# platform_designer_hps_system_hps_0_hps register map
Vendor: default_vendor.com; File version: 0.0
Registers are 32-bit, read-write, reset 0x0 unless marked. A register's access mark holds for its fields unless they carry their own. Offsets are from the block's base; [hi:lo] are bit positions; 'fields as' and 'values as' point back to an identical list.

## clkmgr — Registers in the Clock Manager module
Base 0xFFD04000
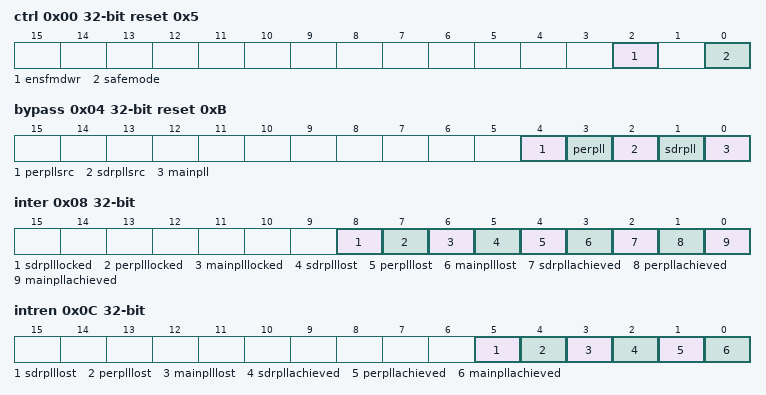
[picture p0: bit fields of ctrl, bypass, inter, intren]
0x00 ctrl reset 0x5 — Contains fields that control the entire Clock Manager.
  [2] ensfmdwr — When set the Clock Manager will respond to a Safe Mode request from the Reset Manager on a warm reset by setting the Safe Mode bit. When clear the clock manager will not set the the Safe Mode bit on a warm reset This bit is cleared on a cold reset. Warm reset has no affect on this bit.
  [0] safemode write-1-clears — When set the Clock Manager is in Safe Mode. In Safe Mode Clock Manager register settings defining clock behavior are ignored and clocks are set to a Safe Mode state.In Safe Mode all clocks with the optional exception of debug clocks, are directly generated from the EOSC1 clock input, all PLLs are bypassed, all programmable dividers are set to 1 and all clocks are enabled. This bit should only be cleared when clocks have been correctly configured This field is set on a cold reset and optionally on a warm reset and may not be set by SW.
0x04 bypass reset 0xB — Contains fields that control bypassing each PLL.
  [4] perpllsrc — This bit defines the bypass source forPeripheral PLL. When changing fields that affect VCO lock the PLL must be bypassed and this bit must be set to OSC1_CLK. The reset value for this bit is applied on a cold reset. Warm reset has no affect on this bit.
    0=SELECT_EOSC1; 1=SELECT_INPUT_MUX
  [3] perpll — When set, causes the Peripheral PLL VCO and counters to be bypassed so that all clocks generated by the Peripheral PLL are directly driven from either eosc1_clk or the Peripheral PLL input clock. The bypass clock source for Peripheral PLL is determined by the Peripheral PLL Bypass Source Register bit. The reset value for this bit is applied on a cold reset. Warm reset has no affect on this bit.
  [2] sdrpllsrc — This bit defines the bypass source forSDRAM PLL. When changing fields that affect VCO lock the PLL must be bypassed and this bit must be set to OSC1_CLK. The reset value for this bit is applied on a cold reset. Warm reset has no affect on this bit.
    0=SELECT_EOSC1; 1=SELECT_INPUT_MUX
  [1] sdrpll — When set, causes the SDRAM PLL VCO and counters to be bypassed so that all clocks generated by the SDRAM PLL are directly driven from either eosc1_clk or the SDRAM PLL input clock. The bypass clock source for SDRAM PLL is determined by the SDRAM PLL Bypass Source Register bit. The reset value for this bit is applied on a cold reset. Warm reset has no affect on this bit.
  [0] mainpll — When set, causes the Main PLL VCO and counters to be bypassed so that all clocks generated by the Main PLL are directly driven from the Main PLL input clock. The bypass source for Main PLL is the external eosc1_clk. The reset value for this bit is applied on a cold reset. Warm reset has no affect on this bit.
0x08 inter (reset mask 0xFFFFFE3F) — Contains fields that indicate the PLL lock status. Fields are only reset by a cold reset.
  [8] sdrplllocked ro — If 1, the SDRAM PLL is currently locked. If 0, the SDRAM PLL is currently not locked.
  [7] perplllocked ro — If 1, the Peripheral PLL is currently locked. If 0, the Peripheral PLL is currently not locked.
  [6] mainplllocked ro — If 1, the Main PLL is currently locked. If 0, the Main PLL is currently not locked.
  [5] sdrplllost write-1-clears — If 1, the SDRAM PLL has lost lock at least once since this bit was cleared. If 0, the SDRAM PLL has not lost lock since this bit was cleared.
  [4] perplllost write-1-clears — If 1, the Peripheral PLL has lost lock at least once since this bit was cleared. If 0, the Peripheral PLL has not lost lock since this bit was cleared.
  [3] mainplllost write-1-clears — If 1, the Main PLL has lost lock at least once since this bit was cleared. If 0, the Main PLL has not lost lock since this bit was cleared.
  [2] sdrpllachieved write-1-clears — If 1, the SDRAM PLL has achieved lock at least once since this bit was cleared. If 0, the SDRAM PLL has not achieved lock since this bit was cleared.
  [1] perpllachieved write-1-clears — If 1, the Peripheral PLL has achieved lock at least once since this bit was cleared. If 0, the Peripheral PLL has not achieved lock since this bit was cleared.
  [0] mainpllachieved write-1-clears — If 1, the Main PLL has achieved lock at least once since this bit was cleared. If 0, the Main PLL has not achieved lock since this bit was cleared.
0x0C intren — Contain fields that enable the interrupt. Fields are only reset by a cold reset.
  [5] sdrplllost — When set to 1, the SDRAM PLL lost lock bit is ORed into the Clock Manager interrupt output. When set to 0 the SDRAM PLL lost lock bit is not ORed into the Clock Manager interrupt output.
  [4] perplllost — When set to 1, the Peripheral PLL lost lock bit is ORed into the Clock Manager interrupt output. When set to 0 the Peripheral PLL lost lock bit is not ORed into the Clock Manager interrupt output.
  [3] mainplllost — When set to 1, the Main PLL lost lock bit is ORed into the Clock Manager interrupt output. When set to 0 the Main PLL lost lock bit is not ORed into the Clock Manager interrupt output.
  [2] sdrpllachieved — When set to 1, the SDRAM PLL achieved lock bit is ORed into the Clock Manager interrupt output. When set to 0 the SDRAM PLL achieved lock bit is not ORed into the Clock Manager interrupt output.
  [1] perpllachieved — When set to 1, the Peripheral PLL achieved lock bit is ORed into the Clock Manager interrupt output. When set to 0 the Peripheral PLL achieved lock bit is not ORed into the Clock Manager interrupt output.
  [0] mainpllachieved — When set to 1, the Main PLL achieved lock bit is ORed into the Clock Manager interrupt output. When set to 0 the Main PLL achieved lock bit is not ORed into the Clock Manager interrupt output.
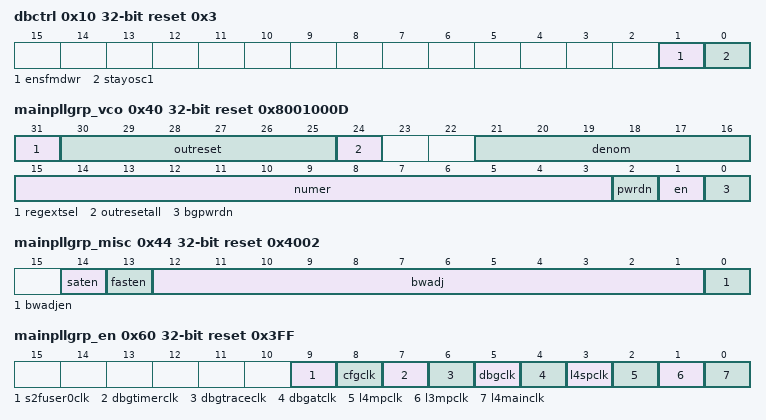
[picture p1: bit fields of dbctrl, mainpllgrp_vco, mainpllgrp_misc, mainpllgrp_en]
0x10 dbctrl reset 0x3 — Contains fields that control the debug clocks.
  [1] ensfmdwr — When this bit is set the debug clocks will be affected by the assertion of Safe Mode on a warm reset if Stay OSC1 is not set. When this bit is clear the debug clocks will not be affected by the assertion of Safe Mode on a warm reset. If Debug Clocks are in Safe Mode they are taken out of Safe Mode when the Safe Mode bit is cleared independent of this bit.The reset value of this bit is applied on a cold reset; warm reset has no affect on this bit.
  [0] stayosc1 — When this bit is set the debug root clock (Main PLL C2 output) will always be bypassed to the EOSC1_clk independent of any other clock manager settings. When clear the debug source will be a function of register settings in the clock manager. Clocks affected by this bit are dbg_at_clk, dbg_clk, dbg_trace_clk, and dbg_timer_clk. The reset value for this bit is applied on a cold reset. Warm reset has no affect on this bit.
0x14 stat ro — Provides status of Hardware Managed Clock transition State Machine.
  [0] busy — This read only bit indicates that the Hardware Managed clock's state machine is active. If the state machine is active, then the clocks are in transition. Software should poll this bit after changing the source of internal clocks when writing to the BYPASS, CTRL or DBCTRL registers. Immediately following writes to any of these registers, SW should wait until this bit is IDLE before proceeding with any other register writes in the Clock Manager. The reset value of this bit is applied on a cold reset; warm reset has no affect on this bit.
    0=IDLE; 1=BUSY
0x40 mainpllgrp_vco reset 0x8001000D — Contains settings that control the Main PLL VCO. The VCO output frequency is the input frequency multiplied by the numerator (M+1) and divided by the denominator (N+1). The VCO input clock source is always eosc1_clk. Fields are only reset by a cold reset.
  [31] regextsel — If set to '1', the external regulator is selected for the PLL. If set to '0', the internal regulator is slected. It is strongly recommended to select the external regulator while the PLL is not enabled (in reset), and then disable the external regulater once the PLL becomes enabled. Software should simulateously update the 'Enable' bit and the 'External Regulator Input Select' in the same write access to the VCO register. When the 'Enable' bit is clear, the 'External Regulator Input Select' should be set, and vice versa. The reset value of this bit is applied on a cold reset; warm reset has no affect on this bit.
  [30:25] outreset — Resets the individual PLL output counter. For software to change the PLL output counter without producing glitches on the respective clock, SW must set the VCO register respective Output Counter Reset bit. Software then polls the respective Output Counter Reset Acknowledge bit in the Output Counter Reset Ack Status Register. Software then writes the appropriate counter register, and then clears the respective VCO register Output Counter Reset bit. LSB 'outreset[0]' corresponds to PLL output clock C0, etc. If set to '1', reset output divider, no clock output from counter. If set to '0', counter is not reset. The reset value of this bit is applied on a cold reset; warm reset has no affect on this bit.
  [24] outresetall — Before releasing Bypass, All Output Counter Reset must be set and cleared by software for correct clock operation. If '1', Reset phase multiplexer and all output counter state. So that after the assertion all the clocks output are start from rising edge align. If '0', phase multiplexer and output counter state not reset and no change to the phase of the clock outputs.
  [21:16] denom — Denominator in VCO output frequency equation. For incremental frequency change, if the new value lead to less than 20% of the frequency change, this value can be changed without resetting the PLL. The Numerator and Denominator can not be changed at the same time for incremental frequency changed.
  [15:3] numer — Numerator in VCO output frequency equation. For incremental frequency change, if the new value lead to less than 20% of the frequency change, this value can be changed without resetting the PLL. The Numerator and Denominator can not be changed at the same time for incremental frequency changed.
  [2] pwrdn — If '1', power down analog circuitry. If '0', analog circuitry not powered down.
  [1] en — If '1', VCO is enabled. If '0', VCO is in reset.
  [0] bgpwrdn — If '1', powers down bandgap. If '0', bandgap is not power down.
0x44 mainpllgrp_misc reset 0x4002 — Contains VCO control signals and other PLL control signals need to be controllable through register. Fields are only reset by a cold reset.
  [14] saten — Enables saturation behavior.
  [13] fasten — Enables fast locking circuit.
  [12:1] bwadj — Provides Loop Bandwidth Adjust value.
  [0] bwadjen — If set to 1, the Loop Bandwidth Adjust value comes from the Loop Bandwidth Adjust field. If set to 0, the Loop Bandwidth Adjust value equals the M field divided by 2 value of the VCO Control Register. The M divided by 2 is the upper 12 bits (12:1) of the M field in the VCO register.
0x48 mainpllgrp_mpuclk — Contains settings that control clock mpu_clk generated from the C0 output of the Main PLL. Only reset by a cold reset.
  [8:0] cnt — Divides the VCO/2 frequency by the value+1 in this field.
0x4C mainpllgrp_mainclk — Contains settings that control clock main_clk generated from the C1 output of the Main PLL. Only reset by a cold reset.
  [8:0] cnt — Divides the VCO/4 frequency by the value+1 in this field.
0x50 mainpllgrp_dbgatclk — Contains settings that control clock dbg_base_clk generated from the C2 output of the Main PLL. Only reset by a cold reset.
  fields as mainpllgrp_mainclk
0x54 mainpllgrp_mainqspiclk reset 0x3 — Contains settings that control clock main_qspi_clk generated from the C3 output of the Main PLL. Only reset by a cold reset.
  [8:0] cnt — Divides the VCO frequency by the value+1 in this field.
0x58 mainpllgrp_mainnandsdmmcclk reset 0x3 — Contains settings that control clock main_nand_sdmmc_clk generated from the C4 output of the Main PLL. Only reset by a cold reset.
  [8:0] cnt — Divides the VCO frequency by the value+1 in this field.
0x5C mainpllgrp_cfgs2fuser0clk reset 0xF — Contains settings that control clock cfg_s2f_user0_clk generated from the C5 output of the Main PLL. Qsys and user documenation refer to cfg_s2f_user0_clk as cfg_h2f_user0_clk. Only reset by a cold reset.
  [8:0] cnt — Divides the VCO frequency by the value+1 in this field.
0x60 mainpllgrp_en reset 0x3FF — Contains fields that control clock enables for clocks derived from the Main PLL. 1: The clock is enabled. 0: The clock is disabled. Fields are only reset by a cold reset.
  [9] s2fuser0clk — Enables clock s2f_user0_clk output. Qsys and user documenation refer to s2f_user0_clk as h2f_user0_clk.
  [8] cfgclk — Enables clock cfg_clk output
  [7] dbgtimerclk — Enables clock dbg_timer_clk output
  [6] dbgtraceclk — Enables clock dbg_trace_clk output
  [5] dbgclk — Enables clock dbg_clk output
  [4] dbgatclk — Enables clock dbg_at_clk output
  [3] l4spclk — Enables clock l4_sp_clk output
  [2] l4mpclk — Enables clock l4_mp_clk output
  [1] l3mpclk — Enables clock l3_mp_clk output
  [0] l4mainclk — Enables clock l4_main_clk output
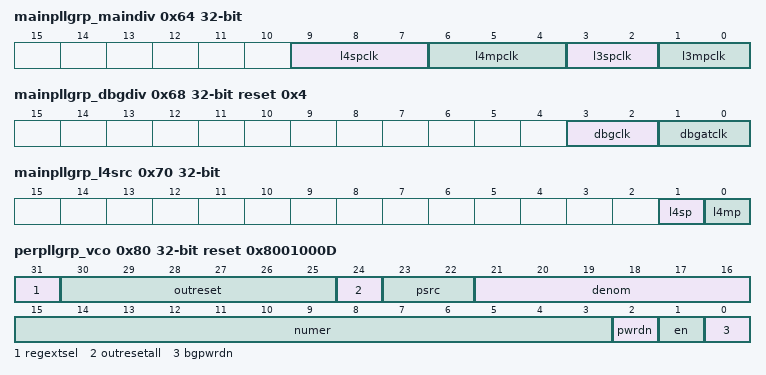
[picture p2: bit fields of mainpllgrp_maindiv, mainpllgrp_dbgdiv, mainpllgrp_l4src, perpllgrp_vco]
0x64 mainpllgrp_maindiv — Contains fields that control clock dividers for main clocks derived from the Main PLL Fields are only reset by a cold reset.
  [9:7] l4spclk — The l4_sp_clk is divided down from the periph_base_clk by the value specified in this field.
    0=Div1; 1=Div2; 2=Div4; 3=Div8; 4=Div16
  [6:4] l4mpclk — The l4_mp_clk is divided down from the periph_base_clk by the value specified in this field.
    0=Div1; 1=Div2; 2=Div4; 3=Div8; 4=Div16
  [3:2] l3spclk — The l3_sp_clk is divided down from the l3_mp_clk by the value specified in this field.
    0=Div1; 1=Div2
  [1:0] l3mpclk — The l3_mp_clk is divided down from the l3_main_clk by the value specified in this field.
    0=Div1; 1=Div2
0x68 mainpllgrp_dbgdiv reset 0x4 — Contains fields that control clock dividers for debug clocks derived from the Main PLL Fields are only reset by a cold reset.
  [3:2] dbgclk — The dbg_clk is divided down from the dbg_at_clk by the value specified in this field.
    1=Div2; 2=Div4
  [1:0] dbgatclk — The dbg_at_clk is divided down from the C2 output of the Main PLL by the value specified in this field.
    0=Div1; 1=Div2; 2=Div4
0x6C mainpllgrp_tracediv — Contains a field that controls the clock divider for the debug trace clock derived from the Main PLL Only reset by a cold reset.
  [2:0] traceclk — The dbg_trace_clk is divided down from the C2 output of the Main PLL by the value specified in this field.
    0=Div1; 1=Div2; 2=Div4; 3=Div8; 4=Div16
0x70 mainpllgrp_l4src — Contains fields that select the clock source for L4 MP and SP APB interconnect Fields are only reset by a cold reset.
  [1] l4sp — Selects the source for l4_sp_clk
    0=MainPLL; 1=PeriphPLL
  [0] l4mp — Selects the source for l4_mp_clk
    0=MainPLL; 1=PeriphPLL
0x74 mainpllgrp_stat ro — Contains Output Clock Counter Reset acknowledge status.
  [5:0] outresetack — These read only bits per PLL output indicate that the PLL has received the Output Reset Counter request and has gracefully stopped the respective PLL output clock. For software to change the PLL output counter without producing glitches on the respective clock, SW must set the VCO register respective Output Counter Reset bit. Software then polls the respective Output Counter Reset Acknowledge bit in the Output Counter Reset Ack Status Register. Software then writes the appropriate counter register, and then clears the respective VCO register Output Counter Reset bit. The reset value of this bit is applied on a cold reset; warm reset has no affect on this bit.
    0=IDLE; 1=ACK_RECEIVED
0x80 perpllgrp_vco reset 0x8001000D — Contains settings that control the Peripheral PLL VCO. The VCO output frequency is the input frequency multiplied by the numerator (M+1) and divided by the denominator (N+1). Fields are only reset by a cold reset.
  [31] regextsel — If set to '1', the external regulator is selected for the PLL. If set to '0', the internal regulator is slected. It is strongly recommended to select the external regulator while the PLL is not enabled (in reset), and then disable the external regulater once the PLL becomes enabled. Software should simulateously update the 'Enable' bit and the 'External Regulator Input Select' in the same write access to the VCO register. When the 'Enable' bit is clear, the 'External Regulator Input Select' should be set, and vice versa. The reset value of this bit is applied on a cold reset; warm reset has no affect on this bit.
  [30:25] outreset — Resets the individual PLL output counter. For software to change the PLL output counter without producing glitches on the respective clock, SW must set the VCO register respective Output Counter Reset bit. Software then polls the respective Output Counter Reset Acknowledge bit in the Output Counter Reset Ack Status Register. Software then writes the appropriate counter register, and then clears the respective VCO register Output Counter Reset bit. LSB 'outreset[0]' corresponds to PLL output clock C0, etc. If set to '1', reset output divider, no clock output from counter. If set to '0', counter is not reset. The reset value of this bit is applied on a cold reset; warm reset has no affect on this bit.
  [24] outresetall — Before releasing Bypass, All Output Counter Reset must be set and cleared by software for correct clock operation. If '1', Reset phase multiplexer and all output counter state. So that after the assertion all the clocks output are start from rising edge align. If '0', phase multiplexer and output counter state not reset and no change to the phase of the clock outputs.
  [23:22] psrc — Controls the VCO input clock source. Qsys and user documenation refer to f2s_periph_ref_clk as f2h_periph_ref_clk.
    0=EOSC1; 1=EOSC2; 2=F2S_Periph_Ref
  [21:16] denom — Denominator in VCO output frequency equation. For incremental frequency change, if the new value lead to less than 20% of the frequency change, this value can be changed without resetting the PLL. The Numerator and Denominator can not be changed at the same time for incremental frequency changed.
  [15:3] numer — Numerator in VCO output frequency equation. For incremental frequency change, if the new value lead to less than 20% of the frequency change, this value can be changed without resetting the PLL. The Numerator and Denominator can not be changed at the same time for incremental frequency changed.
  [2] pwrdn — If '1', power down analog circuitry. If '0', analog circuitry not powered down.
  [1] en — If '1', VCO is enabled. If '0', VCO is in reset.
  [0] bgpwrdn — If '1', powers down bandgap. If '0', bandgap is not power down.
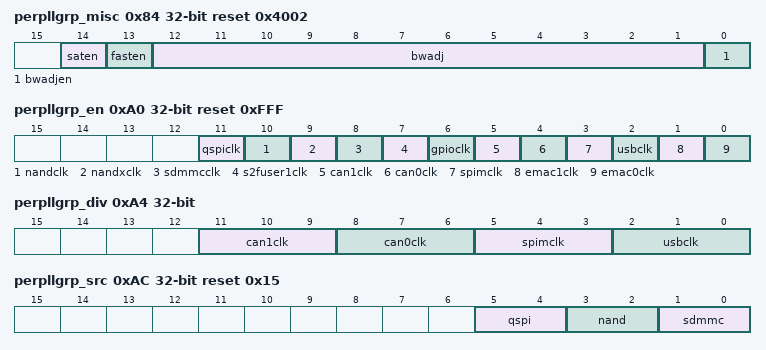
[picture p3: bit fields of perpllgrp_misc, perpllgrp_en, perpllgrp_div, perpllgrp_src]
0x84 perpllgrp_misc reset 0x4002 — Contains VCO control signals and other PLL control signals need to be controllable through register. Fields are only reset by a cold reset.
  fields as mainpllgrp_misc
0x88 perpllgrp_emac0clk reset 0x1 — Contains settings that control clock emac0_clk generated from the C0 output of the Peripheral PLL. Only reset by a cold reset.
  [8:0] cnt — Divides the VCO frequency by the value+1 in this field.
0x8C perpllgrp_emac1clk reset 0x1 — Contains settings that control clock emac1_clk generated from the C1 output of the Peripheral PLL. Only reset by a cold reset.
  [8:0] cnt — Divides the VCO frequency by the value+1 in this field.
0x90 perpllgrp_perqspiclk reset 0x1 — Contains settings that control clock periph_qspi_clk generated from the C2 output of the Peripheral PLL. Only reset by a cold reset.
  [8:0] cnt — Divides the VCO frequency by the value+1 in this field.
0x94 perpllgrp_pernandsdmmcclk reset 0x1 — Contains settings that control clock periph_nand_sdmmc_clk generated from the C3 output of the Peripheral PLL. Only reset by a cold reset.
  [8:0] cnt — Divides the VCO frequency by the value+1 in this field.
0x98 perpllgrp_perbaseclk reset 0x1 — Contains settings that control clock periph_base_clk generated from the C4 output of the Peripheral PLL. Only reset by a cold reset.
  [8:0] cnt — Divides the VCO frequency by the value+1 in this field.
0x9C perpllgrp_s2fuser1clk reset 0x1 — Contains settings that control clock s2f_user1_clk generated from the C5 output of the Peripheral PLL. Qsys and user documenation refer to s2f_user1_clk as h2f_user1_clk. Only reset by a cold reset.
  [8:0] cnt — Divides the VCO frequency by the value+1 in this field.
0xA0 perpllgrp_en reset 0xFFF — Contains fields that control clock enables for clocks derived from the Peripheral PLL 1: The clock is enabled. 0: The clock is disabled. Fields are only reset by a cold reset.
  [11] qspiclk — Enables clock qspi_clk output
  [10] nandclk — Enables clock nand_clk output nand_clk Enable should always be de-asserted before the nand_x_clk Enable, and the nand_x_clk Enable should always be asserted before the nand_clk Enable is asserted. A brief delay is also required between switching the enables (8 * nand_clk period).
  [9] nandxclk — Enables clock nand_x_clk output nand_clk Enable should always be de-asserted before the nand_x_clk Enable, and the nand_x_clk Enable should always be asserted before the nand_clk Enable is asserted. A brief delay is also required between switching the enables (8 * nand_clk period).
  [8] sdmmcclk — Enables clock sdmmc_clk output
  [7] s2fuser1clk — Enables clock s2f_user1_clk output. Qsys and user documenation refer to s2f_user1_clk as h2f_user1_clk.
  [6] gpioclk — Enables clock gpio_clk output
  [5] can1clk — Enables clock can1_clk output
  [4] can0clk — Enables clock can0_clk output
  [3] spimclk — Enables clock spi_m_clk output
  [2] usbclk — Enables clock usb_mp_clk output
  [1] emac1clk — Enables clock emac1_clk output
  [0] emac0clk — Enables clock emac0_clk output
0xA4 perpllgrp_div — Contains fields that control clock dividers for clocks derived from the Peripheral PLL Fields are only reset by a cold reset.
  [all] fields
    0=Div1; 1=Div2; 2=Div4; 3=Div8; 4=Div16
  [11:9] can1clk — The can1_clk is divided down from the periph_base_clk by the value specified in this field.
  [8:6] can0clk — The can0_clk is divided down from the periph_base_clk by the value specified in this field.
  [5:3] spimclk — The spi_m_clk is divided down from the periph_base_clk by the value specified in this field.
  [2:0] usbclk — The usb_mp_clk is divided down from the periph_base_clk by the value specified in this field.
0xA8 perpllgrp_gpiodiv reset 0x1 — Contains a field that controls the clock divider for the GPIO De-bounce clock. Only reset by a cold reset.
  [23:0] gpiodbclk — The gpio_db_clk is divided down from the periph_base_clk by the value plus one specified in this field. The value 0 (divide by 1) is illegal. A value of 1 indicates divide by 2, 2 divide by 3, etc.
0xAC perpllgrp_src reset 0x15 — Contains fields that select the source clocks for the flash controllers. Fields are only reset by a cold reset.
  [5:4] qspi — Selects the source clock for the QSPI. Qsys and user documenation refer to f2s_periph_ref_clk as f2h_periph_ref_clk.
    0=F2s_Periph_Ref_Clk; 1=Main_Qspi_Clk; 2=Periph_Qspi_Clk
  [3:2] nand — Selects the source clock for the NAND. Qsys and user documenation refer to f2s_periph_ref_clk as f2h_periph_ref_clk.
    0=F2s_Periph_Ref_Clk; 1=Main_Nand_Clk; 2=Periph_Nand_Clk
  [1:0] sdmmc — Selects the source clock for the SDMMC. Qsys and user documenation refer to f2s_periph_ref_clk as f2h_periph_ref_clk.
    0=F2s_Periph_Ref_Clk; 1=Main_Nand_Clk; 2=Periph_Nand_Clk
0xB0 perpllgrp_stat ro — Contains Output Clock Counter Reset acknowledge status.
  fields as mainpllgrp_stat
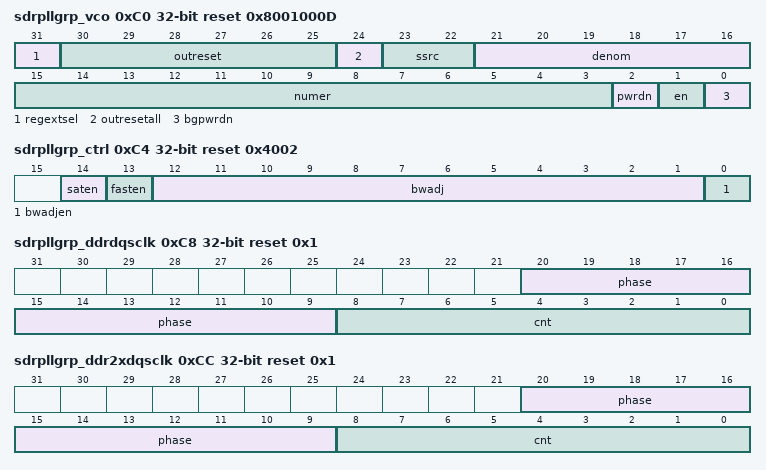
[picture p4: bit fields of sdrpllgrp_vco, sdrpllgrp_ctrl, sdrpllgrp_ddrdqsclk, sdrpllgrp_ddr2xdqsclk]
0xC0 sdrpllgrp_vco reset 0x8001000D — Contains settings that control the SDRAM PLL VCO. The VCO output frequency is the input frequency multiplied by the numerator (M+1) and divided by the denominator (N+1). Fields are only reset by a cold reset.
  [31] regextsel — If set to '1', the external regulator is selected for the PLL. If set to '0', the internal regulator is slected. It is strongly recommended to select the external regulator while the PLL is not enabled (in reset), and then disable the external regulater once the PLL becomes enabled. Software should simulateously update the 'Enable' bit and the 'External Regulator Input Select' in the same write access to the VCO register. When the 'Enable' bit is clear, the 'External Regulator Input Select' should be set, and vice versa. The reset value of this bit is applied on a cold reset; warm reset has no affect on this bit.
  [30:25] outreset — Resets the individual PLL output counter. For software to change the PLL output counter without producing glitches on the respective clock, SW must set the VCO register respective Output Counter Reset bit. Software then polls the respective Output Counter Reset Acknowledge bit in the Output Counter Reset Ack Status Register. Software then writes the appropriate counter register, and then clears the respective VCO register Output Counter Reset bit. LSB 'outreset[0]' corresponds to PLL output clock C0, etc. If set to '1', reset output divider, no clock output from counter. If set to '0', counter is not reset. The reset value of this bit is applied on a cold reset; warm reset has no affect on this bit.
  [24] outresetall — Before releasing Bypass, All Output Counter Reset must be set and cleared by software for correct clock operation. If '1', Reset phase multiplexer and output counter state. So that after the assertion all the clocks output are start from rising edge align. If '0', phase multiplexer and output counter state not reset and no change to the phase of the clock outputs.
  [23:22] ssrc — Controls the VCO input clock source. The PLL must by bypassed to eosc1_clk before changing this field. Qsys and user documenation refer to f2s_sdram_ref_clk as f2h_sdram_ref_clk.
    0=EOSC1; 1=EOSC2; 2=F2S_SDRAM_Ref
  [21:16] denom — Denominator in VCO output frequency equation. For incremental frequency change, if the new value lead to less than 20% of the frequency change, this value can be changed without resetting the PLL. The Numerator and Denominator can not be changed at the same time for incremental frequency changed.
  [15:3] numer — Numerator in VCO output frequency equation. For incremental frequency change, if the new value lead to less than 20% of the frequency change, this value can be changed without resetting the PLL. The Numerator and Denominator can not be changed at the same time for incremental frequency changed.
  [2] pwrdn — If '1', power down analog circuitry. If '0', analog circuitry not powered down.
  [1] en — If '1', VCO is enabled. If '0', VCO is in reset.
  [0] bgpwrdn — If '1', powers down bandgap. If '0', bandgap is not power down.
0xC4 sdrpllgrp_ctrl reset 0x4002 — Contains VCO control signals and other PLL control signals need to be controllable through register. Fields are only reset by a cold reset.
  fields as mainpllgrp_misc
0xC8 sdrpllgrp_ddrdqsclk reset 0x1 — Contains settings that control clock ddr_dqs_clk generated from the C0 output of the SDRAM PLL. Fields are only reset by a cold reset.
  [20:9] phase — Increment the phase of the VCO output by the value in this field multiplied by 45 degrees. The accumulated phase shift is the total shifted amount since the last assertion of the 'SDRAM All Output Divider Reset' bit in the SDRAM vco control register. In order to guarantee the phase shift to a known value, 'SDRAM clocks output phase align' bit should be asserted before programming this field. This field is only writeable by SW when it is zero. HW updates this field in real time as the phase adjustment is being made. SW may poll this field waiting for zero indicating the phase adjustment has completed by HW.
  [8:0] cnt — Divides the VCO frequency by the value+1 in this field.
0xCC sdrpllgrp_ddr2xdqsclk reset 0x1 — Contains settings that control clock ddr_2x_dqs_clk generated from the C1 output of the SDRAM PLL. Fields are only reset by a cold reset.
  fields as sdrpllgrp_ddrdqsclk
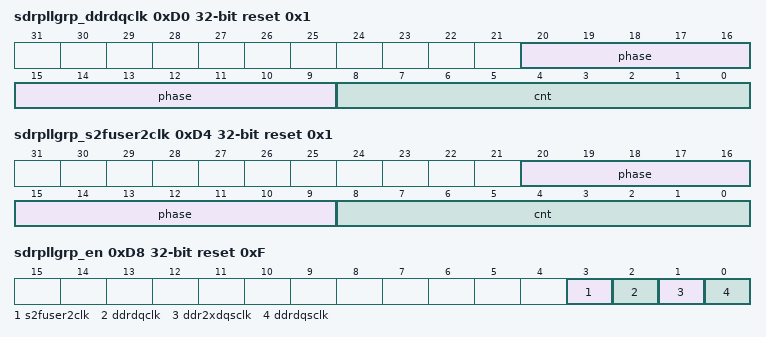
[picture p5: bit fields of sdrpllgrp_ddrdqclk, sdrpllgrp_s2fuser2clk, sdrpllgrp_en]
0xD0 sdrpllgrp_ddrdqclk reset 0x1 — Contains settings that control clock ddr_dq_clk generated from the C2 output of the SDRAM PLL. Fields are only reset by a cold reset.
  fields as sdrpllgrp_ddrdqsclk
0xD4 sdrpllgrp_s2fuser2clk reset 0x1 — Contains settings that control clock s2f_user2_clk generated from the C5 output of the SDRAM PLL. Qsys and user documenation refer to s2f_user2_clk as h2f_user2_clk Fields are only reset by a cold reset.
  fields as sdrpllgrp_ddrdqsclk
0xD8 sdrpllgrp_en reset 0xF — Contains fields that control the SDRAM Clock Group enables generated from the SDRAM PLL clock outputs. 1: The clock is enabled. 0: The clock is disabled. Fields are only reset by a cold reset.
  [3] s2fuser2clk — Enables clock s2f_user2_clk output. Qsys and user documenation refer to s2f_user2_clk as h2f_user2_clk.
  [2] ddrdqclk — Enables clock ddr_dq_clk output
  [1] ddr2xdqsclk — Enables clock ddr_2x_dqs_clk output
  [0] ddrdqsclk — Enables clock ddr_dqs_clk output
0xDC sdrpllgrp_stat ro — Contains Output Clock Counter Reset acknowledge status.
  fields as mainpllgrp_stat
